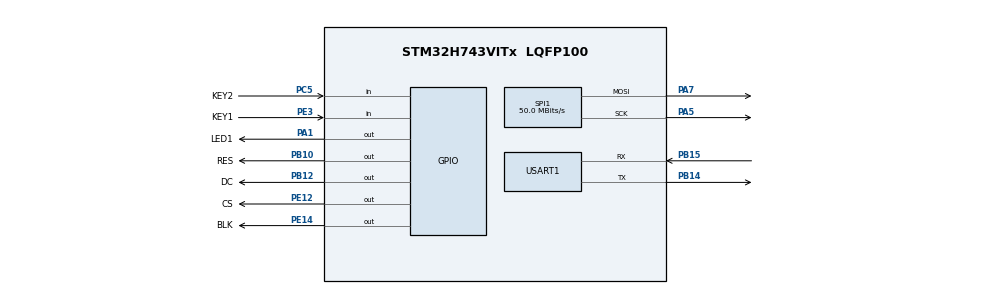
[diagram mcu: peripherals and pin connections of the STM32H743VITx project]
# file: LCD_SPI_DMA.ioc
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Dma.Request0=USART1_RX
Dma.Request1=SPI1_TX
Dma.SPI1_TX.1.Direction=DMA_MEMORY_TO_PERIPH
Dma.SPI1_TX.1.EventEnable=DISABLE
Dma.SPI1_TX.1.FIFOMode=DMA_FIFOMODE_DISABLE
Dma.SPI1_TX.1.Instance=DMA1_Stream3
Dma.SPI1_TX.1.MemDataAlignment=DMA_MDATAALIGN_BYTE
Dma.SPI1_TX.1.MemInc=DMA_MINC_DISABLE
Dma.SPI1_TX.1.Mode=DMA_NORMAL
Dma.SPI1_TX.1.PeriphDataAlignment=DMA_PDATAALIGN_BYTE
Dma.SPI1_TX.1.PeriphInc=DMA_PINC_DISABLE
Dma.SPI1_TX.1.Polarity=HAL_DMAMUX_REQ_GEN_RISING
Dma.SPI1_TX.1.Priority=DMA_PRIORITY_LOW
Dma.SPI1_TX.1.RequestNumber=1
Dma.SPI1_TX.1.SignalID=NONE
Dma.SPI1_TX.1.SyncEnable=DISABLE
Dma.SPI1_TX.1.SyncPolarity=HAL_DMAMUX_SYNC_NO_EVENT
Dma.SPI1_TX.1.SyncRequestNumber=1
Dma.SPI1_TX.1.SyncSignalID=NONE
Dma.USART1_RX.0.Direction=DMA_PERIPH_TO_MEMORY
Dma.USART1_RX.0.EventEnable=DISABLE
Dma.USART1_RX.0.FIFOMode=DMA_FIFOMODE_DISABLE
Dma.USART1_RX.0.Instance=DMA1_Stream0
Dma.USART1_RX.0.MemDataAlignment=DMA_MDATAALIGN_BYTE
Dma.USART1_RX.0.MemInc=DMA_MINC_ENABLE
Dma.USART1_RX.0.Mode=DMA_NORMAL
Dma.USART1_RX.0.PeriphDataAlignment=DMA_PDATAALIGN_BYTE
Dma.USART1_RX.0.PeriphInc=DMA_PINC_DISABLE
Dma.USART1_RX.0.Polarity=HAL_DMAMUX_REQ_GEN_RISING
Dma.USART1_RX.0.Priority=DMA_PRIORITY_LOW
Dma.USART1_RX.0.RequestNumber=1
Dma.USART1_RX.0.SignalID=NONE
Dma.USART1_RX.0.SyncEnable=DISABLE
Dma.USART1_RX.0.SyncPolarity=HAL_DMAMUX_SYNC_NO_EVENT
Dma.USART1_RX.0.SyncRequestNumber=1
Dma.USART1_RX.0.SyncSignalID=NONE
Mcu.Family=STM32H7
Mcu.Name=STM32H743VITx
Mcu.Package=LQFP100
NVIC.DMA1_Stream0_IRQn=true\:0\:0\:false\:false\:true\:false\:true\:true
NVIC.DMA1_Stream3_IRQn=true\:3\:0\:true\:false\:true\:false\:true\:true
NVIC.PriorityGroup=NVIC_PRIORITYGROUP_4
NVIC.SPI1_IRQn=true\:0\:0\:false\:false\:true\:false\:true\:true
PA1.GPIO_Label=LED1
PA1.Signal=GPIO_Output
PA13\ (JTMS/SWDIO).Mode=Serial_Wire
PA13\ (JTMS/SWDIO).Signal=DEBUG_JTMS-SWDIO
PA14\ (JTCK/SWCLK).Mode=Serial_Wire
PA14\ (JTCK/SWCLK).Signal=DEBUG_JTCK-SWCLK
PA5.GPIO_PuPd=GPIO_PULLUP
PA5.GPIO_Speed=GPIO_SPEED_FREQ_VERY_HIGH
PA5.Mode=TX_Only_Simplex_Unidirect_Master
PA5.Signal=SPI1_SCK
PA7.GPIO_PuPd=GPIO_PULLUP
PA7.GPIO_Speed=GPIO_SPEED_FREQ_VERY_HIGH
PA7.Mode=TX_Only_Simplex_Unidirect_Master
PA7.Signal=SPI1_MOSI
PB10.GPIO_Label=RES
PB10.GPIO_Speed=GPIO_SPEED_FREQ_VERY_HIGH
PB10.Signal=GPIO_Output
PB12.GPIO_Label=DC
PB12.GPIO_PuPd=GPIO_PULLUP
PB12.GPIO_Speed=GPIO_SPEED_FREQ_VERY_HIGH
PB12.Signal=GPIO_Output
PB14.Mode=Asynchronous
PB14.Signal=USART1_TX
PB15.Mode=Asynchronous
PB15.Signal=USART1_RX
PC5.GPIO_Label=KEY2
PC5.GPIO_PuPd=GPIO_PULLUP
PC5.Signal=GPIO_Input
PE12.GPIO_Label=CS
PE12.GPIO_PuPd=GPIO_PULLUP
PE12.GPIO_Speed=GPIO_SPEED_FREQ_VERY_HIGH
PE12.Signal=GPIO_Output
PE14.GPIO_Label=BLK
PE14.GPIO_PuPd=GPIO_PULLUP
PE14.Signal=GPIO_Output
PE3.GPIO_Label=KEY1
PE3.GPIO_PuPd=GPIO_PULLUP
PE3.Signal=GPIO_Input
PH0-OSC_IN\ (PH0).Mode=HSE-External-Oscillator
PH0-OSC_IN\ (PH0).Signal=RCC_OSC_IN
PH1-OSC_OUT\ (PH1).Mode=HSE-External-Oscillator
PH1-OSC_OUT\ (PH1).Signal=RCC_OSC_OUT
ProjectManager.HeapSize=0x200
ProjectManager.StackSize=0x400
ProjectManager.TargetToolchain=STM32CubeIDE
RCC.ADCFreq_Value=50390625
RCC.APB1Freq_Value=100000000
RCC.APB2Freq_Value=100000000
RCC.APB3Freq_Value=100000000
RCC.APB4Freq_Value=100000000
RCC.CortexFreq_Value=400000000
RCC.D1PPRE=RCC_APB3_DIV2
RCC.D2PPRE1=RCC_APB1_DIV2
RCC.D2PPRE2=RCC_APB2_DIV2
RCC.D3PPRE=RCC_APB4_DIV2
RCC.DIVM1=2
RCC.DIVN1=64
RCC.DIVQ1=4
RCC.HCLKFreq_Value=200000000
RCC.HPRE=RCC_HCLK_DIV2
RCC.PLLSourceVirtual=RCC_PLLSOURCE_HSE
RCC.ProductRev=revV
RCC.SYSCLKFreq_VALUE=400000000
RCC.SYSCLKSource=RCC_SYSCLKSOURCE_PLLCLK
RCC.USBFreq_Value=200000000
SPI1.BaudRatePrescaler=SPI_BAUDRATEPRESCALER_4
SPI1.CLKPhase=SPI_PHASE_1EDGE
SPI1.CLKPolarity=SPI_POLARITY_LOW
SPI1.CalculateBaudRate=50.0 MBits/s
SPI1.DataSize=SPI_DATASIZE_8BIT
SPI1.Direction=SPI_DIRECTION_2LINES_TXONLY
SPI1.MasterKeepIOState=SPI_MASTER_KEEP_IO_STATE_ENABLE
SPI1.Mode=SPI_MODE_MASTER
SPI1.VirtualType=VM_MASTER
USART1.VirtualMode-Asynchronous=VM_ASYNC
board=custom

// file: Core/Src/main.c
/* USER CODE BEGIN Header */
/**
  ******************************************************************************
  * @file           : main.c
  * @brief          : Main program body
  ******************************************************************************
  * @attention
  *
  * Copyright (c) 2023 STMicroelectronics.
  * All rights reserved.
  *
  * This software is licensed under terms that can be found in the LICENSE file
  * in the root directory of this software component.
  * If no LICENSE file comes with this software, it is provided AS-IS.
  *
  ******************************************************************************
  */
/* USER CODE END Header */
#include "main.h"

SPI_HandleTypeDef hspi1;
DMA_HandleTypeDef hdma_spi1_tx;

UART_HandleTypeDef huart1;
DMA_HandleTypeDef hdma_usart1_rx;

void SystemClock_Config(void);
static void MX_GPIO_Init(void);
static void MX_DMA_Init(void);
static void MX_USART1_UART_Init(void);
static void MX_SPI1_Init(void);

int main(void)
{

  /* MCU Configuration--------------------------------------------------------*/

  /* Reset of all peripherals, Initializes the Flash interface and the Systick. */
  HAL_Init();

  /* Configure the system clock */
  SystemClock_Config();

  /* Initialize all configured peripherals */
  MX_GPIO_Init();
  MX_DMA_Init();
  MX_USART1_UART_Init();
  MX_SPI1_Init();
  /* USER CODE BEGIN 2 */
    HAL_GPIO_WritePin(BLK_GPIO_Port, BLK_Pin, 1);
    LCD_Init();
  /* USER CODE END 2 */

  /* Infinite loop */
  /* USER CODE BEGIN WHILE */
    while (1)
  {
      for(int i = 0; i < 21; i++){
          LCD_Fill(0, 0, LCD_W, LCD_H, color_Fill[i]);
//          HAL_Delay(100);
      }
      HAL_GPIO_TogglePin(LED1_GPIO_Port, LED1_Pin);
    /* USER CODE END WHILE */

  }
}

void SystemClock_Config(void)
{
  RCC_OscInitTypeDef RCC_OscInitStruct = {0};
  RCC_ClkInitTypeDef RCC_ClkInitStruct = {0};

  /** Supply configuration update enable
  */
  HAL_PWREx_ConfigSupply(PWR_LDO_SUPPLY);

  /** Configure the main internal regulator output voltage
  */
  __HAL_PWR_VOLTAGESCALING_CONFIG(PWR_REGULATOR_VOLTAGE_SCALE1);

  while(!__HAL_PWR_GET_FLAG(PWR_FLAG_VOSRDY)) {}

  /** Initializes the RCC Oscillators according to the specified parameters
  * in the RCC_OscInitTypeDef structure.
  */
  RCC_OscInitStruct.OscillatorType = RCC_OSCILLATORTYPE_HSE;
  RCC_OscInitStruct.HSEState = RCC_HSE_ON;
  RCC_OscInitStruct.PLL.PLLState = RCC_PLL_ON;
  RCC_OscInitStruct.PLL.PLLSource = RCC_PLLSOURCE_HSE;
  RCC_OscInitStruct.PLL.PLLM = 2;
  RCC_OscInitStruct.PLL.PLLN = 64;
  RCC_OscInitStruct.PLL.PLLP = 2;
  RCC_OscInitStruct.PLL.PLLQ = 4;
  RCC_OscInitStruct.PLL.PLLR = 2;
  RCC_OscInitStruct.PLL.PLLRGE = RCC_PLL1VCIRANGE_3;
  RCC_OscInitStruct.PLL.PLLVCOSEL = RCC_PLL1VCOWIDE;
  RCC_OscInitStruct.PLL.PLLFRACN = 0;
  if (HAL_RCC_OscConfig(&RCC_OscInitStruct) != HAL_OK)
  {
    Error_Handler();
  }

  /** Initializes the CPU, AHB and APB buses clocks
  */
  RCC_ClkInitStruct.ClockType = RCC_CLOCKTYPE_HCLK|RCC_CLOCKTYPE_SYSCLK
                              |RCC_CLOCKTYPE_PCLK1|RCC_CLOCKTYPE_PCLK2
                              |RCC_CLOCKTYPE_D3PCLK1|RCC_CLOCKTYPE_D1PCLK1;
  RCC_ClkInitStruct.SYSCLKSource = RCC_SYSCLKSOURCE_PLLCLK;
  RCC_ClkInitStruct.SYSCLKDivider = RCC_SYSCLK_DIV1;
  RCC_ClkInitStruct.AHBCLKDivider = RCC_HCLK_DIV2;
  RCC_ClkInitStruct.APB3CLKDivider = RCC_APB3_DIV2;
  RCC_ClkInitStruct.APB1CLKDivider = RCC_APB1_DIV2;
  RCC_ClkInitStruct.APB2CLKDivider = RCC_APB2_DIV2;
  RCC_ClkInitStruct.APB4CLKDivider = RCC_APB4_DIV2;

  if (HAL_RCC_ClockConfig(&RCC_ClkInitStruct, FLASH_LATENCY_2) != HAL_OK)
  {
    Error_Handler();
  }
}

static void MX_SPI1_Init(void)
{

  /* SPI1 parameter configuration*/
  hspi1.Instance = SPI1;
  hspi1.Init.Mode = SPI_MODE_MASTER;
  hspi1.Init.Direction = SPI_DIRECTION_2LINES_TXONLY;
  hspi1.Init.DataSize = SPI_DATASIZE_8BIT;
  hspi1.Init.CLKPolarity = SPI_POLARITY_LOW;
  hspi1.Init.CLKPhase = SPI_PHASE_1EDGE;
  hspi1.Init.NSS = SPI_NSS_SOFT;
  hspi1.Init.BaudRatePrescaler = SPI_BAUDRATEPRESCALER_4;
  hspi1.Init.FirstBit = SPI_FIRSTBIT_MSB;
  hspi1.Init.TIMode = SPI_TIMODE_DISABLE;
  hspi1.Init.CRCCalculation = SPI_CRCCALCULATION_DISABLE;
  hspi1.Init.CRCPolynomial = 0x0;
  hspi1.Init.NSSPMode = SPI_NSS_PULSE_ENABLE;
  hspi1.Init.NSSPolarity = SPI_NSS_POLARITY_LOW;
  hspi1.Init.FifoThreshold = SPI_FIFO_THRESHOLD_01DATA;
  hspi1.Init.TxCRCInitializationPattern = SPI_CRC_INITIALIZATION_ALL_ZERO_PATTERN;
  hspi1.Init.RxCRCInitializationPattern = SPI_CRC_INITIALIZATION_ALL_ZERO_PATTERN;
  hspi1.Init.MasterSSIdleness = SPI_MASTER_SS_IDLENESS_00CYCLE;
  hspi1.Init.MasterInterDataIdleness = SPI_MASTER_INTERDATA_IDLENESS_00CYCLE;
  hspi1.Init.MasterReceiverAutoSusp = SPI_MASTER_RX_AUTOSUSP_DISABLE;
  hspi1.Init.MasterKeepIOState = SPI_MASTER_KEEP_IO_STATE_ENABLE;
  hspi1.Init.IOSwap = SPI_IO_SWAP_DISABLE;
  if (HAL_SPI_Init(&hspi1) != HAL_OK)
  {
    Error_Handler();
  }

}

static void MX_USART1_UART_Init(void)
{

  huart1.Instance = USART1;
  huart1.Init.BaudRate = 115200;
  huart1.Init.WordLength = UART_WORDLENGTH_8B;
  huart1.Init.StopBits = UART_STOPBITS_1;
  huart1.Init.Parity = UART_PARITY_NONE;
  huart1.Init.Mode = UART_MODE_TX_RX;
  huart1.Init.HwFlowCtl = UART_HWCONTROL_NONE;
  huart1.Init.OverSampling = UART_OVERSAMPLING_16;
  huart1.Init.OneBitSampling = UART_ONE_BIT_SAMPLE_DISABLE;
  huart1.Init.ClockPrescaler = UART_PRESCALER_DIV1;
  huart1.AdvancedInit.AdvFeatureInit = UART_ADVFEATURE_NO_INIT;
  if (HAL_UART_Init(&huart1) != HAL_OK)
  {
    Error_Handler();
  }
  if (HAL_UARTEx_SetTxFifoThreshold(&huart1, UART_TXFIFO_THRESHOLD_1_8) != HAL_OK)
  {
    Error_Handler();
  }
  if (HAL_UARTEx_SetRxFifoThreshold(&huart1, UART_RXFIFO_THRESHOLD_1_8) != HAL_OK)
  {
    Error_Handler();
  }
  if (HAL_UARTEx_DisableFifoMode(&huart1) != HAL_OK)
  {
    Error_Handler();
  }

}

static void MX_DMA_Init(void)
{

  /* DMA controller clock enable */
  __HAL_RCC_DMA1_CLK_ENABLE();

  /* DMA interrupt init */
  /* DMA1_Stream0_IRQn interrupt configuration */
  HAL_NVIC_SetPriority(DMA1_Stream0_IRQn, 0, 0);
  HAL_NVIC_EnableIRQ(DMA1_Stream0_IRQn);
  /* DMA1_Stream3_IRQn interrupt configuration */
  HAL_NVIC_SetPriority(DMA1_Stream3_IRQn, 3, 0);
  HAL_NVIC_EnableIRQ(DMA1_Stream3_IRQn);

}

static void MX_GPIO_Init(void)
{
  GPIO_InitTypeDef GPIO_InitStruct = {0};

  /* GPIO Ports Clock Enable */
  __HAL_RCC_GPIOE_CLK_ENABLE();
  __HAL_RCC_GPIOH_CLK_ENABLE();
  __HAL_RCC_GPIOA_CLK_ENABLE();
  __HAL_RCC_GPIOC_CLK_ENABLE();
  __HAL_RCC_GPIOB_CLK_ENABLE();

  /*Configure GPIO pin Output Level */
  HAL_GPIO_WritePin(LED1_GPIO_Port, LED1_Pin, GPIO_PIN_RESET);

  /*Configure GPIO pin Output Level */
  HAL_GPIO_WritePin(GPIOE, CS_Pin|BLK_Pin, GPIO_PIN_RESET);

  /*Configure GPIO pin Output Level */
  HAL_GPIO_WritePin(GPIOB, RES_Pin|DC_Pin, GPIO_PIN_RESET);

  /*Configure GPIO pin : KEY1_Pin */
  GPIO_InitStruct.Pin = KEY1_Pin;
  GPIO_InitStruct.Mode = GPIO_MODE_INPUT;
  GPIO_InitStruct.Pull = GPIO_PULLUP;
  HAL_GPIO_Init(KEY1_GPIO_Port, &GPIO_InitStruct);

  /*Configure GPIO pin : LED1_Pin */
  GPIO_InitStruct.Pin = LED1_Pin;
  GPIO_InitStruct.Mode = GPIO_MODE_OUTPUT_PP;
  GPIO_InitStruct.Pull = GPIO_NOPULL;
  GPIO_InitStruct.Speed = GPIO_SPEED_FREQ_LOW;
  HAL_GPIO_Init(LED1_GPIO_Port, &GPIO_InitStruct);

  /*Configure GPIO pin : KEY2_Pin */
  GPIO_InitStruct.Pin = KEY2_Pin;
  GPIO_InitStruct.Mode = GPIO_MODE_INPUT;
  GPIO_InitStruct.Pull = GPIO_PULLUP;
  HAL_GPIO_Init(KEY2_GPIO_Port, &GPIO_InitStruct);

  /*Configure GPIO pin : CS_Pin */
  GPIO_InitStruct.Pin = CS_Pin;
  GPIO_InitStruct.Mode = GPIO_MODE_OUTPUT_PP;
  GPIO_InitStruct.Pull = GPIO_PULLUP;
  GPIO_InitStruct.Speed = GPIO_SPEED_FREQ_VERY_HIGH;
  HAL_GPIO_Init(CS_GPIO_Port, &GPIO_InitStruct);

  /*Configure GPIO pin : BLK_Pin */
  GPIO_InitStruct.Pin = BLK_Pin;
  GPIO_InitStruct.Mode = GPIO_MODE_OUTPUT_PP;
  GPIO_InitStruct.Pull = GPIO_PULLUP;
  GPIO_InitStruct.Speed = GPIO_SPEED_FREQ_LOW;
  HAL_GPIO_Init(BLK_GPIO_Port, &GPIO_InitStruct);

  /*Configure GPIO pin : RES_Pin */
  GPIO_InitStruct.Pin = RES_Pin;
  GPIO_InitStruct.Mode = GPIO_MODE_OUTPUT_PP;
  GPIO_InitStruct.Pull = GPIO_NOPULL;
  GPIO_InitStruct.Speed = GPIO_SPEED_FREQ_VERY_HIGH;
  HAL_GPIO_Init(RES_GPIO_Port, &GPIO_InitStruct);

  /*Configure GPIO pin : DC_Pin */
  GPIO_InitStruct.Pin = DC_Pin;
  GPIO_InitStruct.Mode = GPIO_MODE_OUTPUT_PP;
  GPIO_InitStruct.Pull = GPIO_PULLUP;
  GPIO_InitStruct.Speed = GPIO_SPEED_FREQ_VERY_HIGH;
  HAL_GPIO_Init(DC_GPIO_Port, &GPIO_InitStruct);

}

void Error_Handler(void)
{
  __disable_irq();
  while (1)
  {
  }
}
